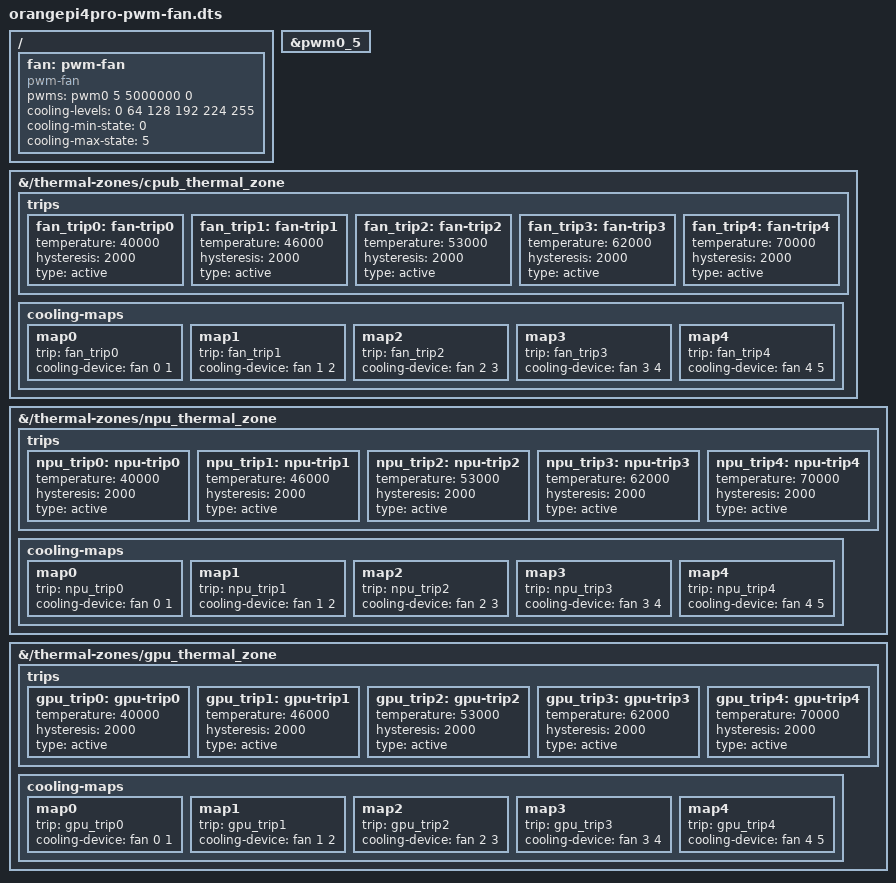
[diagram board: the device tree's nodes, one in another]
/*  For  OrangePi4Pro boards only!! */

/dts-v1/;
/plugin/;

/ {
	/* 1. Enable PWM0 Channel 5 (Physical Pin 32) */
	fragment@0 {
		target = <&pwm0_5>;
		__overlay__ {
			status = "okay";
		};
	};

	/* 2. Create the pwm-fan cooling device */
	fragment@1 {
		target-path = "/";
		__overlay__ {
			fan: pwm-fan {
				compatible = "pwm-fan";
				pwms = <&pwm0 5 5000000 0>; /* channel 0 of pwm0_5, 50000ns =20kHz, 5000000 = 200hz */
				cooling-levels = <0 64 128 192 224 255>;
				cooling-min-state = <0>;
				cooling-max-state = <5>;
				#cooling-cells = <2>;
			};
		};
	};

	/* 3. Bind temperature trips to the Big-core CPU thermal zone */
	fragment@2 {
		target-path = "/thermal-zones/cpub_thermal_zone";
		__overlay__ {
			trips {
				fan_trip0: fan-trip0 { temperature = <40000>; hysteresis = <2000>; type = "active"; };
				fan_trip1: fan-trip1 { temperature = <46000>; hysteresis = <2000>; type = "active"; };
				fan_trip2: fan-trip2 { temperature = <53000>; hysteresis = <2000>; type = "active"; };
				fan_trip3: fan-trip3 { temperature = <62000>; hysteresis = <2000>; type = "active"; };
				fan_trip4: fan-trip4 { temperature = <70000>; hysteresis = <2000>; type = "active"; };
			};

			cooling-maps { 
				map0 { trip = <&fan_trip0>; cooling-device = <&fan 0 1>; };
				map1 { trip = <&fan_trip1>; cooling-device = <&fan 1 2>; };
				map2 { trip = <&fan_trip2>; cooling-device = <&fan 2 3>; };
				map3 { trip = <&fan_trip3>; cooling-device = <&fan 3 4>; };
				map4 { trip = <&fan_trip4>; cooling-device = <&fan 4 5>; };
			};
		};
	}; /* fragment 2 */

	/* 4. NPU Thermal Zone */
	fragment@3 {
		target-path = "/thermal-zones/npu_thermal_zone";
		__overlay__ {
			trips {
				npu_trip0: npu-trip0 { temperature = <40000>; hysteresis = <2000>; type = "active"; };
				npu_trip1: npu-trip1 { temperature = <46000>; hysteresis = <2000>; type = "active"; };
				npu_trip2: npu-trip2 { temperature = <53000>; hysteresis = <2000>; type = "active"; };
				npu_trip3: npu-trip3 { temperature = <62000>; hysteresis = <2000>; type = "active"; };
				npu_trip4: npu-trip4 { temperature = <70000>; hysteresis = <2000>; type = "active"; };
			};

			cooling-maps {
				map0 { trip = <&npu_trip0>; cooling-device = <&fan 0 1>; };
				map1 { trip = <&npu_trip1>; cooling-device = <&fan 1 2>; };
				map2 { trip = <&npu_trip2>; cooling-device = <&fan 2 3>; };
				map3 { trip = <&npu_trip3>; cooling-device = <&fan 3 4>; };
				map4 { trip = <&npu_trip4>; cooling-device = <&fan 4 5>; };
			};
		};
	};

	/* 5. GPU Thermal Zone */
	fragment@4 {
		target-path = "/thermal-zones/gpu_thermal_zone";
		__overlay__ {
			trips {
				gpu_trip0: gpu-trip0 { temperature = <40000>; hysteresis = <2000>; type = "active"; };
				gpu_trip1: gpu-trip1 { temperature = <46000>; hysteresis = <2000>; type = "active"; };
				gpu_trip2: gpu-trip2 { temperature = <53000>; hysteresis = <2000>; type = "active"; };
				gpu_trip3: gpu-trip3 { temperature = <62000>; hysteresis = <2000>; type = "active"; };
				gpu_trip4: gpu-trip4 { temperature = <70000>; hysteresis = <2000>; type = "active"; };
			};

			cooling-maps {
				map0 { trip = <&gpu_trip0>; cooling-device = <&fan 0 1>; };
				map1 { trip = <&gpu_trip1>; cooling-device = <&fan 1 2>; };
				map2 { trip = <&gpu_trip2>; cooling-device = <&fan 2 3>; };
				map3 { trip = <&gpu_trip3>; cooling-device = <&fan 3 4>; };
				map4 { trip = <&gpu_trip4>; cooling-device = <&fan 4 5>; };
			};
		};
	};
};

/* 
	## Notes:
	pwms = <&pwm3 0 50000 0>：
		arg 1 is the phandle for the PWM fan control; default is PWM0 ; 
		arg 2 is the sub node of the phandle, 0 is the default, 5 is for PWM0-5 ( pin 32 )
		arg 3 is the period of the PWM pulse (1/$period = freq)
		arg 4 is unknown.

	cooling-levels = <0 37 88 128 200 255> ：It is used to configure the steppings for the fan speed (PWM duty cycle). 
		The number of steps, and percentage of the duty cycle, are defined here.
		The default configuration defines 6 steps. The range of the speed is 0-255.  (0=0%, 255=100%)
		level=( int( $duty_cycle_percent / (100/256=.390625) ) - 1);
		some fans won't spin up below a 70% duty cycle! (180)

	temp-trips：It is used to configure the corresponding relationship between the CPU temperature and the fan speed. 
		It can be adjusted according to actual needs. The default configuration is:
		(step 0: inferred, anything below step 1)
		step 1: 40 degrees
		step 2: 46
		step 3: 53
		step 4: 62
		step 5: 70 degrees


        ## To install:

        * dtc -A -s -@ -I dts -O dtb -o /boot/dtb/allwinner/overlay/sun60i-a733-pwm-fan.dtbo orangepi4pro-pwm-fan.dts

        *  Edit /boot/armbianEnv.txt (or /boot/orangepiEnv.txt) and add
                overlays=pwm-fan   ( or:  overlays=[existing] pwm-fan )

	*  remove existing pwm0  from overlays, if it exists

        *  Save, update the boot environment, and reboot

*/
